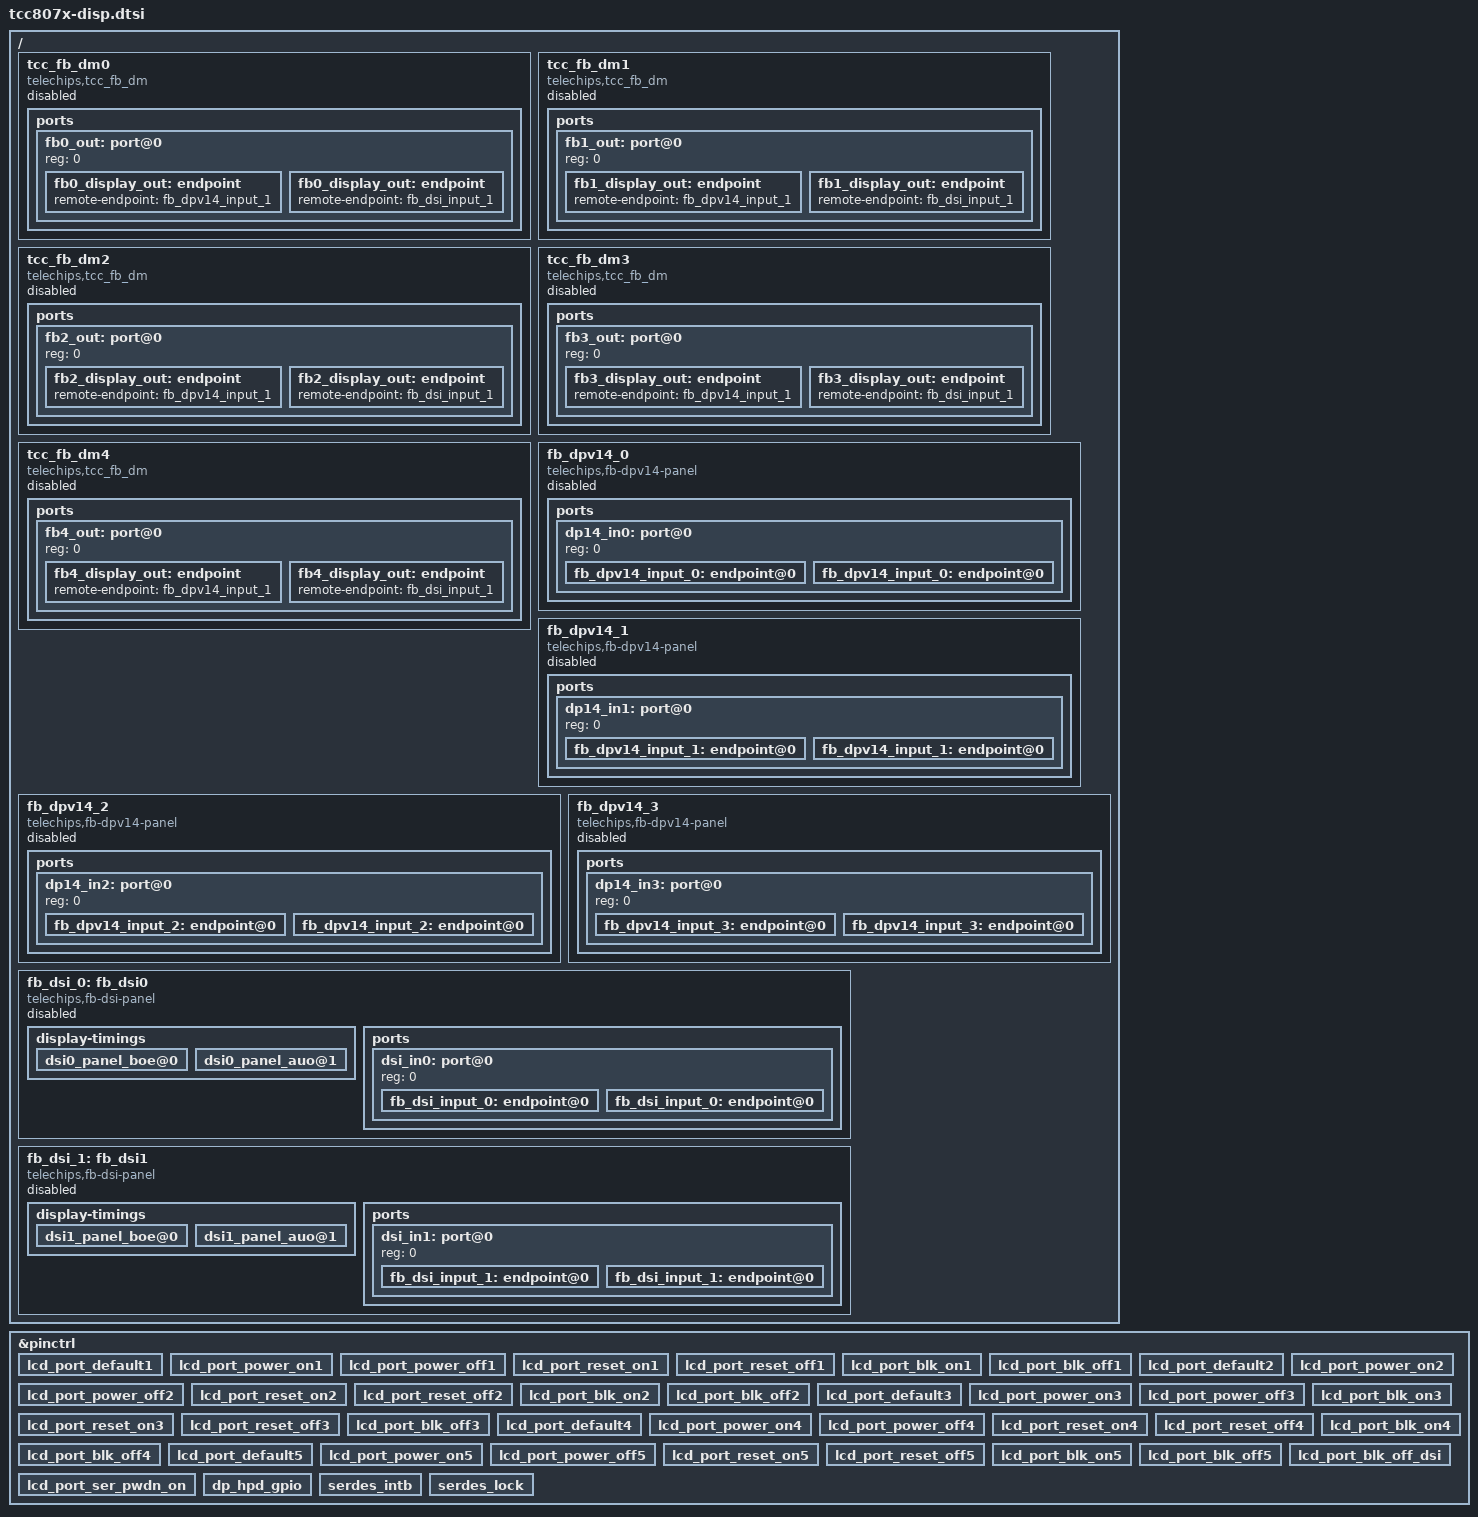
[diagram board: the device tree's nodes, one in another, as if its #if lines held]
// SPDX-License-Identifier: (GPL-2.0-or-later OR MIT)
/*
 * Copyright (C) 2023 Telechips Inc.
 */

#include <dt-bindings/display/telechips-dispdef.h>
#include <dt-bindings/display/tcc807x-vioc.h>
#include <dt-bindings/display/telechips-common-fb_dm_display.h>
#include <dt-bindings/display/tcc807x-fb_dm_display.h>

&pinctrl {
	/* LCD POWER PORT 1 */
	#if defined(LCD_PORT1_PWR) && defined(LCD_PORT1_RST) && \
	defined(LCD_PORT1_BLK)
	lcd_port_default1: lcd_port_default1 {
		telechips,pins = LCD_PORT1_PWR, LCD_PORT1_RST, LCD_PORT1_BLK;
		telechips,pin-function = <0>;
		telechips,no-pull;
	};
	lcd_port_power_on1: lcd_port_power_on1 {
		telechips,pins = LCD_PORT1_PWR;
		telechips,pin-function = <0>;
		telechips,output-high;
	};
	lcd_port_power_off1: lcd_port_power_off1 {
		telechips,pins = LCD_PORT1_PWR;
		telechips,pin-function = <0>;
		telechips,output-low;
	};
	lcd_port_reset_on1: lcd_port_reset_on1 {
		telechips,pins = LCD_PORT1_RST;
		telechips,pin-function = <0>;
		telechips,output-low;
	};
	lcd_port_reset_off1: lcd_port_reset_off1 {
		telechips,pins = LCD_PORT1_RST;
		telechips,pin-function = <0>;
		telechips,output-high;
	};
	lcd_port_blk_on1: lcd_port_blk_on1 {
		telechips,pins = LCD_PORT1_BLK;
		telechips,pin-function = <0>;
		telechips,output-high;
	};
	lcd_port_blk_off1: lcd_port_blk_off1 {
		telechips,pins = LCD_PORT1_BLK;
		telechips,pin-function = <0>;
		telechips,output-low;
	};
	#endif

	/* LCD POWER PORT 2 */
	#if defined(LCD_PORT2_PWR) && defined(LCD_PORT2_RST) && \
	defined(LCD_PORT2_BLK)
	lcd_port_default2: lcd_port_default2 {
		telechips,pins = LCD_PORT2_PWR, LCD_PORT2_RST, LCD_PORT2_BLK;
		telechips,pin-function = <0>;
		telechips,no-pull;
	};
	lcd_port_power_on2: lcd_port_power_on2 {
		telechips,pins = LCD_PORT2_PWR;
		telechips,pin-function = <0>;
		telechips,output-high;
	};
	lcd_port_power_off2: lcd_port_power_off2 {
		telechips,pins = LCD_PORT2_PWR;
		telechips,pin-function = <0>;
		telechips,output-low;
	};
	lcd_port_reset_on2: lcd_port_reset_on2 {
		telechips,pins = LCD_PORT2_RST;
		telechips,pin-function = <0>;
		telechips,output-low;
	};
	lcd_port_reset_off2: lcd_port_reset_off2 {
		telechips,pins = LCD_PORT2_RST;
		telechips,pin-function = <0>;
		telechips,output-high;
	};
	lcd_port_blk_on2: lcd_port_blk_on2 {
		telechips,pins = LCD_PORT2_BLK;
		telechips,pin-function = <0>;
		telechips,output-high;
	};
	lcd_port_blk_off2: lcd_port_blk_off2 {
		telechips,pins = LCD_PORT2_BLK;
		telechips,pin-function = <0>;
		telechips,output-low;
	};
	#endif

	/* LCD POWER PORT 3 */
	#if defined(LCD_PORT3_PWR) && defined(LCD_PORT3_RST) && \
	defined(LCD_PORT3_BLK)
	lcd_port_default3: lcd_port_default3 {
		telechips,pins = LCD_PORT3_PWR, LCD_PORT3_RST, LCD_PORT3_BLK;
		telechips,pin-function = <0>;
		telechips,no-pull;
	};
	/* LVDS power on */
	lcd_port_power_on3: lcd_port_power_on3 {
		telechips,pins = LCD_PORT3_PWR;
		telechips,pin-function = <0>;
		telechips,output-high;
	};
	lcd_port_power_off3: lcd_port_power_off3 {
		telechips,pins = LCD_PORT3_PWR;
		telechips,pin-function = <0>;
		telechips,output-low;
	};
	lcd_port_reset_on3: lcd_port_reset_on3 {
		telechips,pins = LCD_PORT3_RST;
		telechips,pin-function = <0>;
		telechips,output-low;
	};
	lcd_port_reset_off3: lcd_port_reset_off3 {
		telechips,pins = LCD_PORT3_RST;
		telechips,pin-function = <0>;
		telechips,output-high;
	};
	lcd_port_blk_on3: lcd_port_blk_on3 {
		telechips,pins = LCD_PORT3_BLK;
		telechips,pin-function = <0>;
		telechips,output-high;
	};
	lcd_port_blk_off3: lcd_port_blk_off3 {
		telechips,pins = LCD_PORT3_BLK;
		telechips,pin-function = <0>;
		telechips,output-low;
	};
	#endif

	/* LCD POWER PORT 4 */
	#if defined(LCD_PORT4_PWR) && defined(LCD_PORT4_RST) && defined(LCD_PORT4_BLK)
	lcd_port_default4: lcd_port_default4 {
		telechips,pins = LCD_PORT4_PWR, LCD_PORT4_RST, LCD_PORT4_BLK;
		telechips,pin-function = <0>;
		telechips,no-pull;
	};
	lcd_port_power_on4: lcd_port_power_on4 {
		telechips,pins = LCD_PORT4_PWR;
		telechips,pin-function = <0>;
		telechips,output-high;
	};
	lcd_port_power_off4: lcd_port_power_off4 {
		telechips,pins = LCD_PORT4_PWR;
		telechips,pin-function = <0>;
		telechips,output-low;
	};
	lcd_port_reset_on4: lcd_port_reset_on4 {
		telechips,pins = LCD_PORT4_RST;
		telechips,pin-function = <0>;
		telechips,output-low;
	};
	lcd_port_reset_off4: lcd_port_reset_off4 {
		telechips,pins = LCD_PORT4_RST;
		telechips,pin-function = <0>;
		telechips,output-high;
	};
	lcd_port_blk_on4: lcd_port_blk_on4 {
		telechips,pins = LCD_PORT4_BLK;
		telechips,pin-function = <0>;
		telechips,output-high;
	};
	lcd_port_blk_off4: lcd_port_blk_off4 {
		telechips,pins = LCD_PORT4_BLK;
		telechips,pin-function = <0>;
		telechips,output-low;
	};
	#endif

	/* LCD POWER PORT 5 */
	#if defined(LCD_PORT5_PWR) && defined(LCD_PORT5_RST) && defined(LCD_PORT5_BLK)
	lcd_port_default5: lcd_port_default5 {
		telechips,pins = LCD_PORT5_PWR, LCD_PORT5_RST, LCD_PORT5_BLK;
		telechips,pin-function = <0>;
		telechips,no-pull;
	};
	lcd_port_power_on5: lcd_port_power_on5 {
		telechips,pins = LCD_PORT5_PWR;
		telechips,pin-function = <0>;
		telechips,output-high;
	};
	lcd_port_power_off5: lcd_port_power_off5 {
		telechips,pins = LCD_PORT5_PWR;
		telechips,pin-function = <0>;
		telechips,output-low;
	};
	lcd_port_reset_on5: lcd_port_reset_on5 {
		telechips,pins = LCD_PORT5_RST;
		telechips,pin-function = <0>;
		telechips,output-low;
	};
	lcd_port_reset_off5: lcd_port_reset_off5 {
		telechips,pins = LCD_PORT5_RST;
		telechips,pin-function = <0>;
		telechips,output-high;
	};
	lcd_port_blk_on5: lcd_port_blk_on5 {
		telechips,pins = LCD_PORT5_BLK;
		telechips,pin-function = <0>;
		telechips,output-high;
	};
	lcd_port_blk_off5: lcd_port_blk_off5 {
		telechips,pins = LCD_PORT5_BLK;
		telechips,pin-function = <0>;
		telechips,output-low;
	};
	#endif

	lcd_port_blk_off_dsi: lcd_port_blk_off_dsi {
		telechips,pins = LCD_PORT4_BLK, LCD_PORT5_BLK;
		telechips,pin-function = <0>;
		telechips,output-low;
	};

	#if defined(LCD_PORT_SER_PWDN)
	lcd_port_ser_pwdn_on: lcd_port_ser_pwdn_on {
		telechips,pin = LCD_PORT_SER_PWDN;
		telechips,pin-function = <0>;
		telechips,output-high;
	};
	#endif
	#if defined(DP_HPD_GPIO)
	dp_hpd_gpio: dp_hpd_gpio {
		telechips,pins = DP_HPD_GPIO;
		telechips,pin-function = <1>;
		telechips,input-enable;
		telechips,pull-down;
	};
	#endif
	#if defined(DP_SERDES_INTB)
	serdes_intb:serdes_intb {
		telechips,pins = DP_SERDES_INTB;
		telechips,pin-function = <0>;
		telechips,input-enable;
		telechips,no-pull;
	};
	#endif
	#if defined(DP_SERDES_LOCK)
	serdes_lock:serdes_lock {
		telechips,pins = DP_SERDES_LOCK;
		telechips,pin-function = <0>;
		telechips,input-enable;
		telechips,no-pull;
	};
	#endif
};

/ {
	tcc_fb_dm0: tcc_fb_dm0{
		compatible = "telechips,tcc_fb_dm";
		status = "disabled";

		/* clocks = <&clk_peri PERI_LCD0>; */
		lcd-rdma = <VIOC_RDMA00>;
		lcd-wmix = <VIOC_WMIX0>;
		lcd-disp = <VIOC_DISP0>;
		lcd-wdma = <VIOC_WDMA00>;
		lcd-ovp = <24>;
		clk-div = <0>; /* unused for now */
		fb-draw-type = <FB_DRAW_TYPE_BITMAP_HEADER>;
		fb-buf-id = <0>;
		fb-buf-addr = <0x2A000000>;
		bpix = <TCC_VIDEO_BPP32>;
		lcd-mux-id = <3>;

		ports {
			#address-cells = <1>;
			#size-cells = <0>;
			fb0_out: port@0 {
				#address-cells = <1>;
				#size-cells = <0>;
				reg = <0>;
				#if defined(CONFIG_SAMPLE_DTB)
				fb0_display_out: endpoint {
					remote-endpoint = <&fb_dpv14_input_0>;
				};
				fb0_display_out: endpoint {
					remote-endpoint = <&fb_dpv14_input_1>;
				};
				fb0_display_out: endpoint {
					remote-endpoint = <&fb_dpv14_input_2>;
				};
				fb0_display_out: endpoint {
					remote-endpoint = <&fb_dpv14_input_3>;
				};
				fb0_display_out: endpoint {
					remote-endpoint = <&fb_dsi_input_0>;
				};
				fb0_display_out: endpoint {
					remote-endpoint = <&fb_dsi_input_1>;
				};
				#endif
			};
		};
	};

	tcc_fb_dm1: tcc_fb_dm1{
		compatible = "telechips,tcc_fb_dm";
		status = "disabled";

		/* clocks = <&clk_peri PERI_LCD0>; */
		lcd-rdma = <VIOC_RDMA04>;
		lcd-wmix = <VIOC_WMIX1>;
		lcd-disp = <VIOC_DISP1>;
		lcd-wdma = <VIOC_WDMA01>;
		lcd-ovp = <24>;
		clk-div = <0>; /* unused for now */
		fb-draw-type = <FB_DRAW_TYPE_BITMAP_HEADER>;
		fb-buf-id = <1>;
		fb-buf-addr = <0x2A800000>;
		bpix = <TCC_VIDEO_BPP32>;
		lcd-mux-id = <1>;

		ports {
			#address-cells = <1>;
			#size-cells = <0>;

			fb1_out: port@0 {
				#address-cells = <1>;
				#size-cells = <0>;
				reg = <0>;
				#if defined(CONFIG_SAMPLE_DTB)
				fb1_display_out: endpoint {
					remote-endpoint = <&fb_dpv14_input_0>;
				};
				fb1_display_out: endpoint {
					remote-endpoint = <&fb_dpv14_input_1>;
				};
				fb1_display_out: endpoint {
					remote-endpoint = <&fb_dpv14_input_2>;
				};
				fb1_display_out: endpoint {
					remote-endpoint = <&fb_dpv14_input_3>;
				};
				fb1_display_out: endpoint {
					remote-endpoint = <&fb_dsi_input_0>;
				};
				fb1_display_out: endpoint {
					remote-endpoint = <&fb_dsi_input_1>;
				};
				#endif
			};
		};
	};

	tcc_fb_dm2: tcc_fb_dm2 {
		compatible = "telechips,tcc_fb_dm";
		status = "disabled";

		/* clocks = <&clk_peri PERI_LCD0>; */
		lcd-rdma = <VIOC_RDMA08>;
		lcd-wmix = <VIOC_WMIX2>;
		lcd-disp = <VIOC_DISP2>;
		lcd-wdma = <VIOC_WDMA02>;
		lcd-ovp = <24>;
		clk-div = <0>; /* unused for now */
		fb-draw-type = <FB_DRAW_TYPE_BITMAP_HEADER>;
		fb-buf-id = <2>;
		fb-buf-addr = <0x2B000000>;
		bpix = <TCC_VIDEO_BPP32>;
		lcd-mux-id = <2>;

		ports {
			#address-cells = <1>;
			#size-cells = <0>;
			fb2_out: port@0 {
				#address-cells = <1>;
				#size-cells = <0>;
				reg = <0>;
				#if defined(CONFIG_SAMPLE_DTB)
				fb2_display_out: endpoint {
					remote-endpoint = <&fb_dpv14_input_0>;
				};
				fb2_display_out: endpoint {
					remote-endpoint = <&fb_dpv14_input_1>;
				};
				fb2_display_out: endpoint {
					remote-endpoint = <&fb_dpv14_input_2>;
				};
				fb2_display_out: endpoint {
					remote-endpoint = <&fb_dpv14_input_3>;
				};
				fb2_display_out: endpoint {
					remote-endpoint = <&fb_dsi_input_0>;
				};
				fb2_display_out: endpoint {
					remote-endpoint = <&fb_dsi_input_1>;
				};
				#endif
			};
		};
	};

	tcc_fb_dm3: tcc_fb_dm3 {
		compatible = "telechips,tcc_fb_dm";
		status = "disabled";

		/* clocks = <&clk_peri PERI_LCD0>; */
		lcd-rdma = <VIOC_RDMA16>;
		lcd-wmix = <>;
		lcd-disp = <VIOC_DISP3>;
		lcd-wdma = <>;
		lcd-ovp = <24>;
		clk-div = <0>; /* unused for now */
		fb-draw-type = <FB_DRAW_TYPE_BITMAP_HEADER>;
		fb-buf-id = <3>;
		fb-buf-addr = <0x2B800000>;
		bpix = <TCC_VIDEO_BPP32>;
		lcd-mux-id = <0>;

		ports {
			#address-cells = <1>;
			#size-cells = <0>;
			fb3_out: port@0 {
				#address-cells = <1>;
				#size-cells = <0>;
				reg = <0>;
				#if defined(CONFIG_SAMPLE_DTB)
				fb3_display_out: endpoint {
					remote-endpoint = <&fb_dpv14_input_0>;
				};
				fb3_display_out: endpoint {
					remote-endpoint = <&fb_dpv14_input_1>;
				};
				fb3_display_out: endpoint {
					remote-endpoint = <&fb_dpv14_input_2>;
				};
				fb3_display_out: endpoint {
					remote-endpoint = <&fb_dpv14_input_3>;
				};
				fb3_display_out: endpoint {
					remote-endpoint = <&fb_dsi_input_0>;
				};
				fb3_display_out: endpoint {
					remote-endpoint = <&fb_dsi_input_1>;
				};
				#endif
			};
		};
	};

	tcc_fb_dm4: tcc_fb_dm4 {
		compatible = "telechips,tcc_fb_dm";
		status = "disabled";

		/* clocks = <&clk_peri PERI_LCD0>; */
		lcd-rdma = <VIOC_RDMA17>;
		lcd-wmix = <>;
		lcd-disp = <VIOC_DISP4>;
		lcd-wdma = <>;
		lcd-ovp = <24>;
		clk-div = <0>; /* unused for now */
		fb-draw-type = <FB_DRAW_TYPE_BITMAP_HEADER>;
		fb-buf-id = <3>;
		fb-buf-addr = <0x2C000000>;
		bpix = <TCC_VIDEO_BPP32>;
		lcd-mux-id = <4>;

		ports {
			#address-cells = <1>;
			#size-cells = <0>;

			fb4_out: port@0 {
				#address-cells = <1>;
				#size-cells = <0>;
				reg = <0>;
				#if defined(CONFIG_SAMPLE_DTB)
				fb4_display_out: endpoint {
					remote-endpoint = <&fb_dpv14_input_0>;
				};
				fb4_display_out: endpoint {
					remote-endpoint = <&fb_dpv14_input_1>;
				};
				fb4_display_out: endpoint {
					remote-endpoint = <&fb_dpv14_input_2>;
				};
				fb4_display_out: endpoint {
					remote-endpoint = <&fb_dpv14_input_3>;
				};
				fb4_display_out: endpoint {
					remote-endpoint = <&fb_dsi_input_0>;
				};
				fb4_display_out: endpoint {
					remote-endpoint = <&fb_dsi_input_1>;
				};
				#endif
			};
		};
	};

	fb_dpv14_0: fb_dpv14_0 {
		compatible = "telechips,fb-dpv14-panel";
		status = "disabled";

		dp-panel-mode = <DPCFG_PANEL_MODE>;
		dp-serdes-i2c-port = <I2C_PORT_TO_SERDES>; /* For PANEL_MODE_ON */
		dp-vic = <DPCFG_DP0_VIC DPCFG_DP1_VIC DPCFG_DP2_VIC DPCFG_DP3_VIC>;
		dp-vcp_id = <DPCFG_DP0_VCP DPCFG_DP1_VCP DPCFG_DP2_VCP DPCFG_DP3_VCP>;
		dp-phy-lane-swap = <PHY_LANE_SWAP_ON>;
		dp-sdm-bypass = <DPCFG_SDM>;
		dp-trvc-bypass = <DPCFG_TRVC>;
		dp-pixel-encoding = <DPCFG_ENCODING>;
		dp-max-lane = <DPCFG_MAX_LANE>;
		dp-max-rate = <DPCFG_RATE>;

		/* Board configuration */
		phy_model = <DPTX_PHY_DEVICE_SEC>;
		phy_lane_swap = "true";
		evb_power_type = <TCC_EVB_LCD_FOUR_POW>;

		pinctrl-names = "default", "lcd_on", "reset_off",
				"blk_on", "blk_off", "reset_on", "lcd_off",
				"dp_hpd", "serdes_intb", "serdes_lock";
		pinctrl-0 = <>;
		pinctrl-1 = <>;
		pinctrl-2 = <>;
		pinctrl-3 = <>;
		pinctrl-4 = <>;
		pinctrl-5 = <>;
		pinctrl-6 = <>;
		pinctrl-7 = <>;
		pinctrl-8 = <>;
		pinctrl-9 = <>;
		ports {
		#address-cells = <1>;
		#size-cells = <0>;

			dp14_in0:port@0 {
				#address-cells = <1>;
				#size-cells = <0>;
				reg = <0>;
				#if defined(CONFIG_SAMPLE_DTB)
				fb_dpv14_input_0: endpoint@0 {
					reg = <0>;
					remote-endpoint = <&fb0_display_out>;
				};
				fb_dpv14_input_0: endpoint@0 {
					reg = <0>;
					remote-endpoint = <&fb1_display_out>;
				};
				fb_dpv14_input_0: endpoint@0 {
					reg = <0>;
					remote-endpoint = <&fb2_display_out>;
				};
				fb_dpv14_input_0: endpoint@0 {
					reg = <0>;
					remote-endpoint = <&fb3_display_out>;
				};
				fb_dpv14_input_0: endpoint@0 {
					reg = <0>;
					remote-endpoint = <&fb4_display_out>;
				};
				#endif
			};
		};
	};

	fb_dpv14_1: fb_dpv14_1 {
		compatible = "telechips,fb-dpv14-panel";
		status = "disabled";

		pinctrl-names = "default", "lcd_on", "reset_off",
				"blk_on", "blk_off", "reset_on", "lcd_off";
		pinctrl-0 = <>;
		pinctrl-1 = <>;
		pinctrl-2 = <>;
		pinctrl-3 = <>;
		pinctrl-4 = <>;
		pinctrl-5 = <>;
		pinctrl-6 = <>;
		ports {
			#address-cells = <1>;
			#size-cells = <0>;
			dp14_in1:port@0 {
				#address-cells = <1>;
				#size-cells = <0>;
				reg = <0>;
				#if defined(CONFIG_SAMPLE_DTB)
				fb_dpv14_input_1: endpoint@0 {
					reg = <0>;
					remote-endpoint = <&fb0_display_out>;
				};
				fb_dpv14_input_1: endpoint@0 {
					reg = <0>;
					remote-endpoint = <&fb1_display_out>;
				};
				fb_dpv14_input_1: endpoint@0 {
					reg = <0>;
					remote-endpoint = <&fb2_display_out>;
				};
				fb_dpv14_input_1: endpoint@0 {
					reg = <0>;
					remote-endpoint = <&fb3_display_out>;
				};
				fb_dpv14_input_1: endpoint@0 {
					reg = <0>;
					remote-endpoint = <&fb4_display_out>;
				};
				#endif
			};
		};
	};
	fb_dpv14_2: fb_dpv14_2 {
		compatible = "telechips,fb-dpv14-panel";
		status = "disabled";

		pinctrl-names = "default", "lcd_on", "reset_off",
				"blk_on", "blk_off", "reset_on", "lcd_off";
		pinctrl-0 = <>;
		pinctrl-1 = <>;
		pinctrl-2 = <>;
		pinctrl-3 = <>;
		pinctrl-4 = <>;
		pinctrl-5 = <>;
		pinctrl-6 = <>;
		ports {
			#address-cells = <1>;
			#size-cells = <0>;

			dp14_in2:port@0 {
				#address-cells = <1>;
				#size-cells = <0>;
				reg = <0>;
				#if defined(CONFIG_SAMPLE_DTB)
				fb_dpv14_input_2: endpoint@0 {
					reg = <0>;
					remote-endpoint = <&fb0_display_out>;
				};
				fb_dpv14_input_2: endpoint@0 {
					reg = <0>;
					remote-endpoint = <&fb1_display_out>;
				};
				fb_dpv14_input_2: endpoint@0 {
					reg = <0>;
					remote-endpoint = <&fb2_display_out>;
				};
				fb_dpv14_input_2: endpoint@0 {
					reg = <0>;
					remote-endpoint = <&fb3_display_out>;
				};
				fb_dpv14_input_2: endpoint@0 {
					reg = <0>;
					remote-endpoint = <&fb4_display_out>;
				};
				#endif
			};
		};
	};

	fb_dpv14_3: fb_dpv14_3 {
		compatible = "telechips,fb-dpv14-panel";
		status = "disabled";

		pinctrl-names = "default", "lcd_on", "reset_off",
				"blk_on", "blk_off", "reset_on", "lcd_off";
		pinctrl-0 = <>;
		pinctrl-1 = <>;
		pinctrl-2 = <>;
		pinctrl-3 = <>;
		pinctrl-4 = <>;
		pinctrl-5 = <>;
		pinctrl-6 = <>;
		ports {
			#address-cells = <1>;
			#size-cells = <0>;
			dp14_in3:port@0 {
				#address-cells = <1>;
				#size-cells = <0>;
				reg = <0>;
				#if defined(CONFIG_SAMPLE_DTB)
				fb_dpv14_input_3: endpoint@0 {
					reg = <0>;
					remote-endpoint = <&fb0_display_out>;
				};
				fb_dpv14_input_3: endpoint@0 {
					reg = <0>;
					remote-endpoint = <&fb1_display_out>;
				};
				fb_dpv14_input_3: endpoint@0 {
					reg = <0>;
					remote-endpoint = <&fb2_display_out>;
				};
				fb_dpv14_input_3: endpoint@0 {
					reg = <0>;
					remote-endpoint = <&fb3_display_out>;
				};
				fb_dpv14_input_3: endpoint@0 {
					reg = <0>;
					remote-endpoint = <&fb4_display_out>;
				};
				#endif
			};
		};
	};

	fb_dsi_0: fb_dsi0 {
		compatible = "telechips,fb-dsi-panel";
		status = "disabled";
		panel-index = <DSI0_PANEL_INDEX>;
		dsi-port = <DSI_PORT0>;
		auto-mode = <DSI_AUTO>;
		no_of_lane = <DSI_PHY_LANE2>;
		dsi-sdm-bypass = <SDM_BYPASS_ENABLE>;
		dsi-trvc-bypass = <TRVC_BYPASS_ENABLE>;
		pinctrl-names = "default", "lcd_on", "reset_off",
				"blk_on", "blk_off", "reset_on", "lcd_off", "ser_pwdn_on";
		pinctrl-0 = <>;
		pinctrl-1 = <>;
		pinctrl-2 = <>;
		pinctrl-3 = <>;
		pinctrl-4 = <>;
		pinctrl-5 = <>;
		pinctrl-6 = <>;
		#if defined(LCD_PORT_SER_PWDN)
		pinctrl-7 = <&lcd_port_ser_pwdn_on>;
		#else
		pinctrl-7 = <>;
		#endif
		display-timings {
			dsi0_panel_boe@0 {
				clock-frequency = <90000000>; //Ref
				hactive = <1920>;
				vactive = <720>;
				hfront-porch = <28>;
				hback-porch = <28>;
				hsync-len = <8>;
				hsync-active = <1>;
				vback-porch = <10>;
				vfront-porch = <10>;
				vsync-len = <1>;
				vsync-active = <1>;
				de-active = <1>;
				pixelclk-active = <1>;
			};
			dsi0_panel_auo@1 {
				clock-frequency = <100000000>;
				hactive = <1920>;
				vactive = <720>;
				hfront-porch = <356>;
				hback-porch = <96>;
				hsync-len = <8>;
				hsync-active = <1>;
				vback-porch = <3>;
				vfront-porch = <36>;
				vsync-len = <1>;
				vsync-active = <1>;
				de-active = <1>;
				pixelclk-active = <1>;
			};
		};
		ports {
			#address-cells = <1>;
			#size-cells = <0>;
			dsi_in0: port@0 {
				#address-cells = <1>;
				#size-cells = <0>;
				reg = <0>;
				#if defined(CONFIG_SAMPLE_DTB)
				fb_dsi_input_0: endpoint@0 {
					reg = <0>;
					remote-endpoint = <&fb0_display_out>;
				};
				fb_dsi_input_0: endpoint@0 {
					reg = <0>;
					remote-endpoint = <&fb1_display_out>;
				};
				fb_dsi_input_0: endpoint@0 {
					reg = <0>;
					remote-endpoint = <&fb2_display_out>;
				};
				fb_dsi_input_0: endpoint@0 {
					reg = <0>;
					remote-endpoint = <&fb3_display_out>;
				};
				fb_dsi_input_0: endpoint@0 {
					reg = <0>;
					remote-endpoint = <&fb4_display_out>;
				};
				#endif
			};
		};
	};

	fb_dsi_1: fb_dsi1 {
		compatible = "telechips,fb-dsi-panel";
		status = "disabled";
		panel-index = <DSI1_PANEL_INDEX>;
		dsi-port = <DSI_PORT1>;
		auto-mode = <DSI_AUTO>;
		no_of_lane = <DSI_PHY_LANE2>;
		dsi-sdm-bypass = <SDM_BYPASS_ENABLE>;
		dsi-trvc-bypass = <TRVC_BYPASS_ENABLE>;
		pinctrl-names = "default", "lcd_on", "reset_off",
				"blk_on", "blk_off", "reset_on", "lcd_off", "ser_pwdn_on";
		pinctrl-0 = <>;
		pinctrl-1 = <>;
		pinctrl-2 = <>;
		pinctrl-3 = <>;
		pinctrl-4 = <>;
		pinctrl-5 = <>;
		pinctrl-6 = <>;
		#if defined(LCD_PORT_SER_PWDN)
		pinctrl-7 = <&lcd_port_ser_pwdn_on>;
		#else
		pinctrl-7 = <>;
		#endif
		display-timings {
			dsi1_panel_boe@0 {
				clock-frequency = <90000000>; //Ref
				hactive = <1920>;
				vactive = <720>;
				hfront-porch = <28>;
				hback-porch = <28>;
				hsync-len = <8>;
				hsync-active = <1>;
				vback-porch = <10>;
				vfront-porch = <10>;
				vsync-len = <1>;
				vsync-active = <1>;
				de-active = <1>;
				pixelclk-active = <1>;
			};
			dsi1_panel_auo@1 {
				clock-frequency = <100000000>;
				hactive = <1920>;
				vactive = <720>;
				hfront-porch = <356>;
				hback-porch = <96>;
				hsync-len = <8>;
				hsync-active = <1>;
				vback-porch = <3>;
				vfront-porch = <36>;
				vsync-len = <1>;
				vsync-active = <1>;
				de-active = <1>;
				pixelclk-active = <1>;
			};
		};
		ports {
			#address-cells = <1>;
			#size-cells = <0>;
			dsi_in1: port@0 {
				#address-cells = <1>;
				#size-cells = <0>;
				reg = <0>;
				#if defined(CONFIG_SAMPLE_DTB)
				fb_dsi_input_1: endpoint@0 {
					reg = <0>;
					remote-endpoint = <&fb0_display_out>;
				};
				fb_dsi_input_1: endpoint@0 {
					reg = <0>;
					remote-endpoint = <&fb1_display_out>;
				};
				fb_dsi_input_1: endpoint@0 {
					reg = <0>;
					remote-endpoint = <&fb2_display_out>;
				};
				fb_dsi_input_1: endpoint@0 {
					reg = <0>;
					remote-endpoint = <&fb3_display_out>;
				};
				fb_dsi_input_1: endpoint@0 {
					reg = <0>;
					remote-endpoint = <&fb4_display_out>;
				};
				#endif
			};
		};
	};
};
